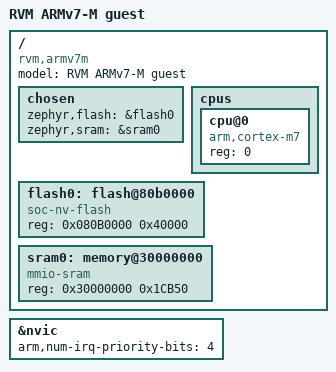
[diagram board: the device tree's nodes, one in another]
/*
 * SPDX-License-Identifier: Unlicense
 *
 * Minimal RVM ARMv7-M guest board.  Everything except the CPU and the RVM
 * code/data windows is deliberately absent; applications add the devices
 * they are granted through app.overlay.
 */

/dts-v1/;

#include <arm/armv7-m.dtsi>

&nvic {
	arm,num-irq-priority-bits = <4>;
};

/ {
	model = "RVM ARMv7-M guest";
	compatible = "rvm,armv7m";

	chosen {
		zephyr,flash = &flash0;
		zephyr,sram = &sram0;
	};

	cpus {
		#address-cells = <1>;
		#size-cells = <0>;

		cpu@0 {
			compatible = "arm,cortex-m7";
			reg = <0>;
		};
	};

	flash0: flash@80b0000 {
		compatible = "soc-nv-flash";
		reg = <0x080B0000 0x40000>;
	};

	sram0: memory@30000000 {
		compatible = "mmio-sram";
		reg = <0x30000000 0x1CB50>;
	};
};
